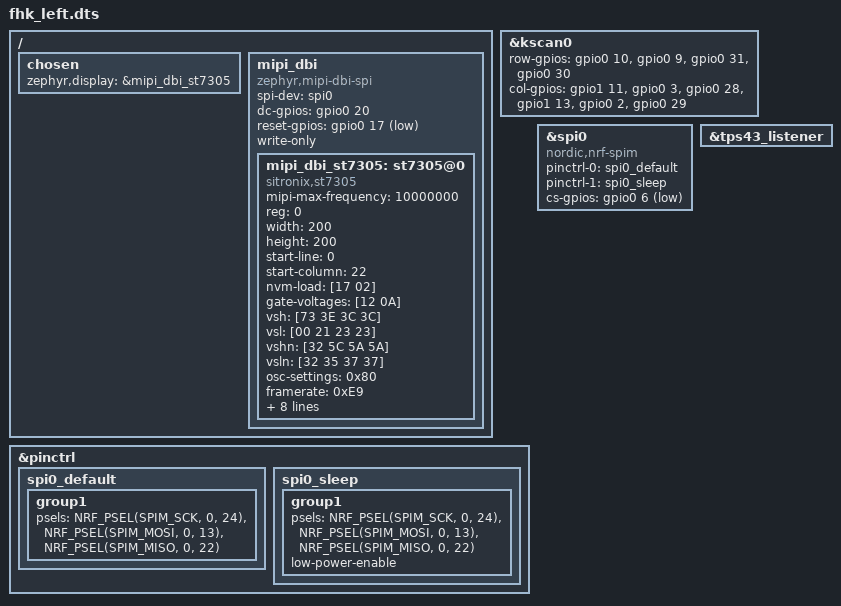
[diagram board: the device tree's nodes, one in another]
/*
*
* Copyright (c) 2024 The ZMK Contributors
* SPDX-License-Identifier: MIT
*
*/

#include "fhk.dtsi"
#include <zephyr/dt-bindings/mipi_dbi/mipi_dbi.h>

&kscan0 {
    row-gpios
        = <&gpio0 10 (GPIO_ACTIVE_HIGH | GPIO_PULL_DOWN)>
        , <&gpio0 9 (GPIO_ACTIVE_HIGH | GPIO_PULL_DOWN)>
        , <&gpio0 31 (GPIO_ACTIVE_HIGH | GPIO_PULL_DOWN)>
        , <&gpio0 30 (GPIO_ACTIVE_HIGH | GPIO_PULL_DOWN)>
        ;
    col-gpios
        = <&gpio1 11 GPIO_ACTIVE_HIGH>
        , <&gpio0 3 GPIO_ACTIVE_HIGH>
        , <&gpio0 28 GPIO_ACTIVE_HIGH>
        , <&gpio1 13 GPIO_ACTIVE_HIGH>
        , <&gpio0 2 GPIO_ACTIVE_HIGH>
        , <&gpio0 29 GPIO_ACTIVE_HIGH>
        ;
};

&pinctrl {
    spi0_default: spi0_default {
        group1 {
            psels = <NRF_PSEL(SPIM_SCK, 0, 24)>,
                <NRF_PSEL(SPIM_MOSI, 0, 13)>,
                <NRF_PSEL(SPIM_MISO, 0, 22)>;
        };
    };

    spi0_sleep: spi0_sleep {
        group1 {
            psels = <NRF_PSEL(SPIM_SCK, 0, 24)>,
                <NRF_PSEL(SPIM_MOSI, 0, 13)>,
                <NRF_PSEL(SPIM_MISO, 0, 22)>;
            low-power-enable;
        };
    };
};

&spi0 {
    compatible = "nordic,nrf-spim";
    status = "okay";
    pinctrl-0 = <&spi0_default>;
    pinctrl-1 = <&spi0_sleep>;
    pinctrl-names = "default", "sleep";
    cs-gpios = <&gpio0 6 GPIO_ACTIVE_LOW>;
};

/ {
    chosen {
        zephyr,display = &mipi_dbi_st7305;
    };  

    mipi_dbi {
        compatible = "zephyr,mipi-dbi-spi";
        status = "okay";
        spi-dev = <&spi0>;
        dc-gpios = <&gpio0 20 GPIO_ACTIVE_HIGH>;
	    reset-gpios = <&gpio0 17 GPIO_ACTIVE_LOW>;
        write-only;
		#address-cells = <1>;
		#size-cells = <0>;

        mipi_dbi_st7305: st7305@0 {
            compatible = "sitronix,st7305";
            mipi-max-frequency = <10000000>;
            reg = <0>;
            width = <200>;
		    height = <200>;
		    start-line = <0>;
		    start-column = <22>;
            nvm-load = [17 02];
            gate-voltages = [12 0A];
            vsh = [73 3E 3C 3C];
    	    vsl = [00 21 23 23];
    	    vshn = [32 5C 5A 5A];
    	    vsln = [32 35 37 37];
            osc-settings = <0x80>;
    	    framerate = <0xE9>;
		    multiplex-ratio = <0x32>;
    	    source-voltage = <0x00>;
		    remap-value = <0x48>;
	        panel-settings = <0x29>;
            hpm-gate-waveform = [E5 F6 17 77 77 77 77 77 77 71];
            lpm-gate-waveform = [05 46 77 77 77 77 76 45];
            mipi-mode = "MIPI_DBI_MODE_SPI_4WIRE";
        };
    };    
};

&tps43_listener {
    status = "okay";
};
